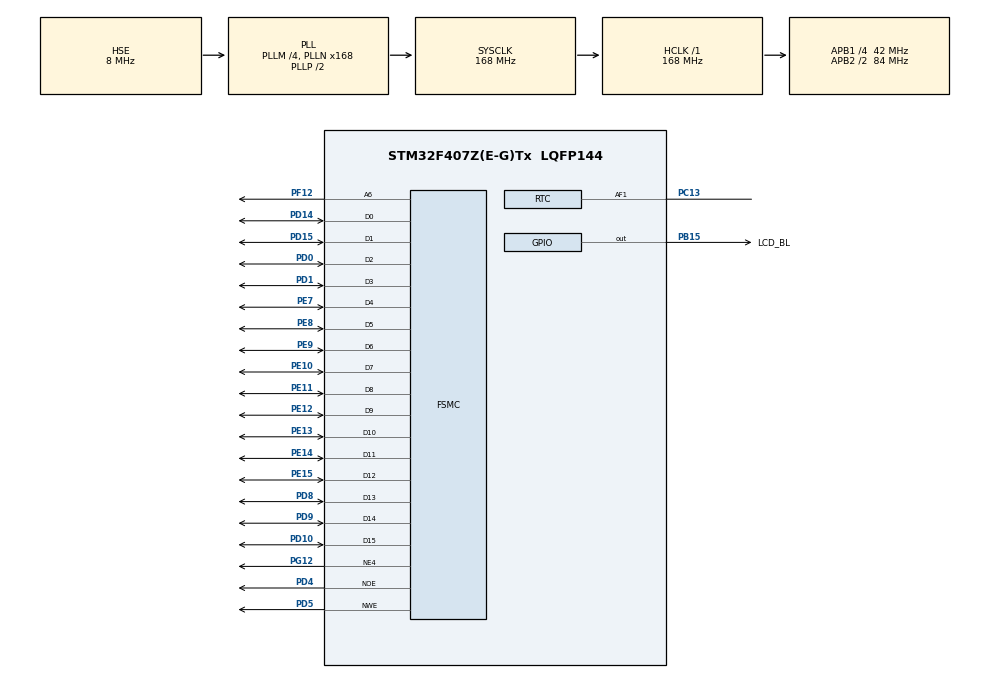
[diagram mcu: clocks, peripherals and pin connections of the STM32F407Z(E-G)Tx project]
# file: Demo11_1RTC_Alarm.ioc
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FSMC.AccessMode4=FSMC_ACCESS_MODE_A
FSMC.AddressSetupTime4=2
FSMC.BusTurnAroundDuration4=0
FSMC.DataSetupTime4=16
FSMC.ExtendedAccessMode4=FSMC_ACCESS_MODE_A
FSMC.ExtendedAddressSetupTime4=4
FSMC.ExtendedBusTurnAroundDuration4=0
FSMC.ExtendedDataSetupTime4=9
FSMC.ExtendedMode4=FSMC_EXTENDED_MODE_ENABLE
FSMC.MemoryType4=FSMC_MEMORY_TYPE_SRAM
FSMC.NSBank4=FSMC_NORSRAM_BANK4
FSMC.WriteOperation4=FSMC_WRITE_OPERATION_ENABLE
Mcu.Family=STM32F4
Mcu.Name=STM32F407Z(E-G)Tx
Mcu.Package=LQFP144
NVIC.PriorityGroup=NVIC_PRIORITYGROUP_2
NVIC.RTC_Alarm_IRQn=true\:1\:1\:true\:false\:true\:true\:true\:true
NVIC.RTC_WKUP_IRQn=true\:1\:0\:true\:false\:true\:true\:true\:true
PA13.Mode=Serial_Wire
PA13.Signal=SYS_JTMS-SWDIO
PA14.Mode=Serial_Wire
PA14.Signal=SYS_JTCK-SWCLK
PB15.GPIO_Label=LCD_BL
PB15.PinState=GPIO_PIN_RESET
PB15.Signal=GPIO_Output
PC13-ANTI_TAMP.Mode=WakeUpAF1
PC13-ANTI_TAMP.Signal=RTC_AF1
PC14-OSC32_IN.Mode=LSE-External-Oscillator
PC14-OSC32_IN.Signal=RCC_OSC32_IN
PC15-OSC32_OUT.Mode=LSE-External-Oscillator
PC15-OSC32_OUT.Signal=RCC_OSC32_OUT
PD0.Signal=FSMC_D2_DA2
PD1.Signal=FSMC_D3_DA3
PD10.Signal=FSMC_D15_DA15
PD14.Signal=FSMC_D0_DA0
PD15.Signal=FSMC_D1_DA1
PD4.Signal=FSMC_NOE
PD5.Signal=FSMC_NWE
PD8.Signal=FSMC_D13_DA13
PD9.Signal=FSMC_D14_DA14
PE10.Signal=FSMC_D7_DA7
PE11.Signal=FSMC_D8_DA8
PE12.Signal=FSMC_D9_DA9
PE13.Signal=FSMC_D10_DA10
PE14.Signal=FSMC_D11_DA11
PE15.Signal=FSMC_D12_DA12
PE7.Signal=FSMC_D4_DA4
PE8.Signal=FSMC_D5_DA5
PE9.Signal=FSMC_D6_DA6
PF12.Signal=FSMC_A6
PG12.Mode=NorPsramChipSelect4_4
PG12.Signal=FSMC_NE4
PH0-OSC_IN.Mode=HSE-External-Oscillator
PH0-OSC_IN.Signal=RCC_OSC_IN
PH1-OSC_OUT.Mode=HSE-External-Oscillator
PH1-OSC_OUT.Signal=RCC_OSC_OUT
ProjectManager.HeapSize=0x200
ProjectManager.StackSize=0x400
ProjectManager.TargetToolchain=STM32CubeIDE
RCC.48MHZClocksFreq_Value=84000000
RCC.AHBFreq_Value=168000000
RCC.APB1CLKDivider=RCC_HCLK_DIV4
RCC.APB1Freq_Value=42000000
RCC.APB1TimFreq_Value=84000000
RCC.APB2CLKDivider=RCC_HCLK_DIV2
RCC.APB2Freq_Value=84000000
RCC.APB2TimFreq_Value=168000000
RCC.CortexFreq_Value=168000000
RCC.FLatency=FLASH_LATENCY_5
RCC.HCLKFreq_Value=168000000
RCC.HSE_VALUE=8000000
RCC.HSI_VALUE=16000000
RCC.PLLM=4
RCC.PLLN=168
RCC.PLLSourceVirtual=RCC_PLLSOURCE_HSE
RCC.RCC_RTC_Clock_Source=RCC_RTCCLKSOURCE_LSE
RCC.RCC_RTC_Clock_SourceVirtual=RCC_RTCCLKSOURCE_LSE
RCC.SYSCLKFreq_VALUE=168000000
RCC.SYSCLKSource=RCC_SYSCLKSOURCE_PLLCLK
RCC.VCOOutputFreq_Value=336000000
RTC.Alarm=RTC_ALARM_A
RTC.AlarmDateWeekDay=3
RTC.AlarmMaskDateWeekDay=RTC_ALARMMASK_DATEWEEKDAY
RTC.AlarmMaskDateWeekDay_B=RTC_ALARMMASK_DATEWEEKDAY
RTC.AlarmMaskHours=RTC_ALARMMASK_HOURS
RTC.AlarmMaskHours_B=RTC_ALARMMASK_HOURS
RTC.AlarmMaskMinutes_B=RTC_ALARMMASK_MINUTES
RTC.Alarm_B=RTC_ALARM_B
RTC.Date=16
RTC.Format=RTC_FORMAT_BIN
RTC.Hours=7
RTC.Hours_A=8
RTC.Hours_B=10
RTC.Minutes=15
RTC.Minutes_A=16
RTC.Minutes_B=20
RTC.Month=RTC_MONTH_MARCH
RTC.OutPutPolarity=RTC_OUTPUT_POLARITY_LOW
RTC.Seconds=10
RTC.Seconds_A=5
RTC.Seconds_B=30
RTC.WakeUpClock=RTC_WAKEUPCLOCK_CK_SPRE_16BITS
RTC.WeekDay=RTC_WEEKDAY_SATURDAY
RTC.Year=19
SH.FSMC_A6.0=FSMC_A6,A6_4
SH.FSMC_D0_DA0.0=FSMC_D0,16b-d4
SH.FSMC_D10_DA10.0=FSMC_D10,16b-d4
SH.FSMC_D11_DA11.0=FSMC_D11,16b-d4
SH.FSMC_D12_DA12.0=FSMC_D12,16b-d4
SH.FSMC_D13_DA13.0=FSMC_D13,16b-d4
SH.FSMC_D14_DA14.0=FSMC_D14,16b-d4
SH.FSMC_D15_DA15.0=FSMC_D15,16b-d4
SH.FSMC_D1_DA1.0=FSMC_D1,16b-d4
SH.FSMC_D2_DA2.0=FSMC_D2,16b-d4
SH.FSMC_D3_DA3.0=FSMC_D3,16b-d4
SH.FSMC_D4_DA4.0=FSMC_D4,16b-d4
SH.FSMC_D5_DA5.0=FSMC_D5,16b-d4
SH.FSMC_D6_DA6.0=FSMC_D6,16b-d4
SH.FSMC_D7_DA7.0=FSMC_D7,16b-d4
SH.FSMC_D8_DA8.0=FSMC_D8,16b-d4
SH.FSMC_D9_DA9.0=FSMC_D9,16b-d4
SH.FSMC_NOE.0=FSMC_NOE,Lcd4
SH.FSMC_NWE.0=FSMC_NWE,Lcd4
VP_RTC_VS_RTC_Activate.Mode=RTC_Enabled
VP_RTC_VS_RTC_Alarm_A_Intern.Mode=Alarm A
VP_RTC_VS_RTC_Alarm_B_Intern.Mode=Alarm B
VP_RTC_VS_RTC_Calendar.Mode=RTC_Calendar
board=custom

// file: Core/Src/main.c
/* USER CODE BEGIN Header */
/**
  ******************************************************************************
  * @file           : main.c
  * @brief          : Main program body
  ******************************************************************************
  * @attention
  *
  * Copyright (c) 2022 STMicroelectronics.
  * All rights reserved.
  *
  * This software is licensed under terms that can be found in the LICENSE file
  * in the root directory of this software component.
  * If no LICENSE file comes with this software, it is provided AS-IS.
  *
  ******************************************************************************
  */
/* USER CODE END Header */
#include "main.h"
#include "rtc.h"
#include "gpio.h"
#include "fsmc.h"

/* USER CODE BEGIN Includes */
#include "lcd.h"
/* USER CODE END Includes */

void SystemClock_Config(void);

int main(void)
{

  /* MCU Configuration--------------------------------------------------------*/

  /* Reset of all peripherals, Initializes the Flash interface and the Systick. */
  HAL_Init();

  /* Configure the system clock */
  SystemClock_Config();

  /* Initialize all configured peripherals */
  MX_GPIO_Init();
  MX_FSMC_Init();
  MX_RTC_Init();
  /* USER CODE BEGIN 2 */
  lcd_init();
  lcd_show_str(10, 10, 24, "Demo11_1:RTC and Alarm", RED);
  lcd_show_str(0, 120, 16, "Alarm A(xx:16:05) trigger: 0", RED);
  lcd_show_str(0, 150, 16, "Alarm B(xx:xx:30) trigger: 0", RED);
  /* USER CODE END 2 */

  /* Infinite loop */
  while (1)
  {

  }
}

void SystemClock_Config(void)
{
  RCC_OscInitTypeDef RCC_OscInitStruct = {0};
  RCC_ClkInitTypeDef RCC_ClkInitStruct = {0};

  /** Configure the main internal regulator output voltage
  */
  __HAL_RCC_PWR_CLK_ENABLE();
  __HAL_PWR_VOLTAGESCALING_CONFIG(PWR_REGULATOR_VOLTAGE_SCALE1);

  /** Initializes the RCC Oscillators according to the specified parameters
  * in the RCC_OscInitTypeDef structure.
  */
  RCC_OscInitStruct.OscillatorType = RCC_OSCILLATORTYPE_HSE|RCC_OSCILLATORTYPE_LSE;
  RCC_OscInitStruct.HSEState = RCC_HSE_ON;
  RCC_OscInitStruct.LSEState = RCC_LSE_ON;
  RCC_OscInitStruct.PLL.PLLState = RCC_PLL_ON;
  RCC_OscInitStruct.PLL.PLLSource = RCC_PLLSOURCE_HSE;
  RCC_OscInitStruct.PLL.PLLM = 4;
  RCC_OscInitStruct.PLL.PLLN = 168;
  RCC_OscInitStruct.PLL.PLLP = RCC_PLLP_DIV2;
  RCC_OscInitStruct.PLL.PLLQ = 4;
  if (HAL_RCC_OscConfig(&RCC_OscInitStruct) != HAL_OK)
  {
    Error_Handler();
  }

  /** Initializes the CPU, AHB and APB buses clocks
  */
  RCC_ClkInitStruct.ClockType = RCC_CLOCKTYPE_HCLK|RCC_CLOCKTYPE_SYSCLK
                              |RCC_CLOCKTYPE_PCLK1|RCC_CLOCKTYPE_PCLK2;
  RCC_ClkInitStruct.SYSCLKSource = RCC_SYSCLKSOURCE_PLLCLK;
  RCC_ClkInitStruct.AHBCLKDivider = RCC_SYSCLK_DIV1;
  RCC_ClkInitStruct.APB1CLKDivider = RCC_HCLK_DIV4;
  RCC_ClkInitStruct.APB2CLKDivider = RCC_HCLK_DIV2;

  if (HAL_RCC_ClockConfig(&RCC_ClkInitStruct, FLASH_LATENCY_5) != HAL_OK)
  {
    Error_Handler();
  }
}

void Error_Handler(void)
{
  __disable_irq();
  while (1)
  {
  }
}
